AUTOSAR XML (schema 4-3-0)
package /ARRoot
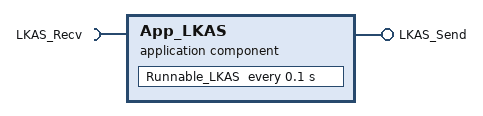
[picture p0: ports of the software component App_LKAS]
  application sw component type App_LKAS
    provide port LKAS_Send: provided-interface=LKAS_Send
      provided-com-specs:
        data-element=RIGHT_STEER, network-representation=compu-method=ISignal_LKAS_Send_RIGHT_STEER
        data-element=LEFT_STEER, network-representation=compu-method=ISignal_LKAS_Send_LEFT_STEER
    require port LKAS_Recv: required-interface=LKAS_Recv
      required-com-specs:
        data-element=LKAS_TRIGGER, network-representation=compu-method=ISignal_LKAS_Recv_LKAS_TRIGGER
        data-element=STEER_VALUE, network-representation=compu-method=ISignal_LKAS_Recv_STEER_VALUE
    behavior InternalBehavior
      timing event TE_Runnable_LKAS: start-on-event=Runnable_LKAS, period=0.1
      runnable Runnable_LKAS: symbol=Runnable_LKAS_100ms
        data-receive-point-by-arguments:
          access DRPBA_Runnable_LKAS_LKAS_Recv_LKAS_TRIGGER: accessed-variable=LKAS_Recv.LKAS_TRIGGER, scope=COMMUNICATION-INTER-ECU
          access DRPBA_Runnable_LKAS_LKAS_Recv_STEER_VALUE: accessed-variable=LKAS_Recv.STEER_VALUE, scope=COMMUNICATION-INTER-ECU
        data-send-points:
          access DSP_Runnable_LKAS_LKAS_Send_RIGHT_STEER: accessed-variable=LKAS_Send.RIGHT_STEER, scope=COMMUNICATION-INTER-ECU
          access DSP_Runnable_LKAS_LKAS_Send_LEFT_STEER: accessed-variable=LKAS_Send.LEFT_STEER, scope=COMMUNICATION-INTER-ECU
